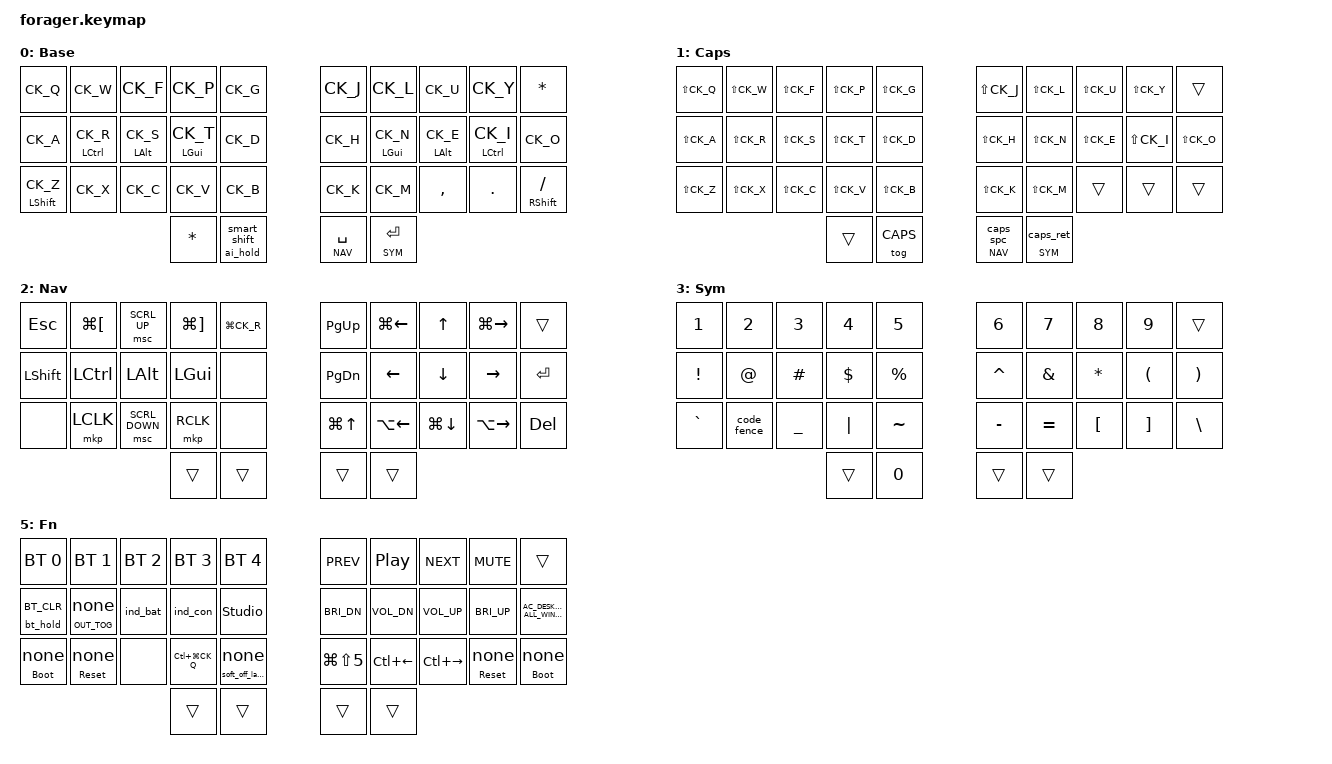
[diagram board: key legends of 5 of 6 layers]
/*
 * Forager keymap for a macOS, AI-agent and browser heavy workflow.
 *
 * Plain Colemak through the Mac's Colemak input source (see mac_colemak.h).
 * Layers: Base, Caps (caps word), Nav (hold Space), Sym (hold Enter),
 * AI (hold the shift thumb) and Fn (hold the shift thumb + Space).
 *
 * Two switches are dead on this board: the left outer thumb (30) and the
 * top-right key (9). Both type * on every layer, only so a repaired switch
 * is easy to test, and Backspace is the L + U combo.
 *
 * Key positions:
 *    0  1  2  3  4     5  6  7  8  9
 *   10 11 12 13 14    15 16 17 18 19
 *   20 21 22 23 24    25 26 27 28 29
 *            30 31    32 33
 */

#include <behaviors.dtsi>
#include <behaviors/rgbled_widget.dtsi>
#include <dt-bindings/zmk/keys.h>
#include <dt-bindings/zmk/bt.h>
#include <dt-bindings/zmk/outputs.h>
#include <dt-bindings/zmk/pointing.h>
#include "mac_colemak.h"

#define BASE 0
#define CAPS 1
#define NAV  2
#define SYM  3
#define AI   4
#define FN   5

#define KEYS_L 0 1 2 3 4 10 11 12 13 14 20 21 22 23 24
#define KEYS_R 5 6 7 8 9 15 16 17 18 19 25 26 27 28 29
#define THUMBS 30 31 32 33

&sk {
    release-after-ms = <600>;
    quick-release;
};

/ {
    behaviors {
        // Home-row mods (and the shift holds on Z and /) only fire with a key
        // from the other hand or a thumb, and never right after typing, so
        // fast rolls stay letters.
        hml: home_row_mod_left {
            compatible = "zmk,behavior-hold-tap";
            #binding-cells = <2>;
            flavor = "balanced";
            tapping-term-ms = <280>;
            quick-tap-ms = <175>;
            require-prior-idle-ms = <150>;
            hold-trigger-key-positions = <KEYS_R THUMBS>;
            hold-trigger-on-release;
            bindings = <&kp>, <&kp>;
        };
        hmr: home_row_mod_right {
            compatible = "zmk,behavior-hold-tap";
            #binding-cells = <2>;
            flavor = "balanced";
            tapping-term-ms = <280>;
            quick-tap-ms = <175>;
            require-prior-idle-ms = <150>;
            hold-trigger-key-positions = <KEYS_L THUMBS>;
            hold-trigger-on-release;
            bindings = <&kp>, <&kp>;
        };

        // Shift + Backspace deletes a word
        bspc_word: backspace_word {
            compatible = "zmk,behavior-mod-morph";
            #binding-cells = <0>;
            bindings = <&kp BSPC>, <&kp LA(BSPC)>;
            mods = <(MOD_LSFT|MOD_RSFT)>;
        };

        // Left inner thumb: tap for one-shot shift (twice for caps), hold
        // 1/4 s for AI. Tap-preferred, so only time picks AI: shift pressed
        // together with a letter always gives a capital, never a ⌘ shortcut.
        ai_shift: ai_shift {
            compatible = "zmk,behavior-hold-tap";
            #binding-cells = <2>;
            flavor = "tap-preferred";
            tapping-term-ms = <250>;
            quick-tap-ms = <175>;
            bindings = <&ai_hold>, <&smart_shift>;
        };

        // Space on the AI layer: hold for Fn. Hold-preferred with no idle
        // check, so it reaches Fn even when pressed right after the AI thumb.
        fn_spc: fn_space {
            compatible = "zmk,behavior-hold-tap";
            #binding-cells = <2>;
            flavor = "hold-preferred";
            tapping-term-ms = <200>;
            bindings = <&mo>, <&kp>;
        };

        // Right outer thumb: tap Enter, hold Sym. Hold-preferred, so a key
        // pressed during the hold always gives a symbol and never sends a
        // half-written prompt.
        sym_ret: sym_enter {
            compatible = "zmk,behavior-hold-tap";
            #binding-cells = <2>;
            flavor = "hold-preferred";
            tapping-term-ms = <170>;
            bindings = <&mo>, <&kp>;
        };
        sym_caps: sym_enter_caps {
            compatible = "zmk,behavior-hold-tap";
            #binding-cells = <2>;
            flavor = "hold-preferred";
            tapping-term-ms = <170>;
            bindings = <&mo>, <&caps_ret>;
        };

        // Right inner thumb: tap Space, hold Nav
        nav_spc: nav_space {
            compatible = "zmk,behavior-hold-tap";
            #binding-cells = <2>;
            flavor = "balanced";
            tapping-term-ms = <200>;
            quick-tap-ms = <175>;
            require-prior-idle-ms = <125>;
            bindings = <&mo>, <&kp>;
        };
        nav_caps: nav_space_caps {
            compatible = "zmk,behavior-hold-tap";
            #binding-cells = <2>;
            flavor = "balanced";
            tapping-term-ms = <200>;
            quick-tap-ms = <175>;
            require-prior-idle-ms = <125>;
            bindings = <&mo>, <&caps_spc>;
        };

        // One-shot shift, tap twice for caps word. Caps word is a layer
        // because ZMK's &caps_word won't shift CK_O (SEMI).
        smart_shift: smart_shift {
            compatible = "zmk,behavior-mod-morph";
            #binding-cells = <0>;
            bindings = <&sk LSHFT>, <&tog CAPS>;
            mods = <(MOD_LSFT|MOD_RSFT)>;
        };

        // ⌘ stays down from the first ⌘Tab until the AI thumb is released
        kt_on: key_toggle_on {
            compatible = "zmk,behavior-key-toggle";
            #binding-cells = <1>;
            toggle-mode = "on";
        };
        kt_off: key_toggle_off {
            compatible = "zmk,behavior-key-toggle";
            #binding-cells = <1>;
            toggle-mode = "off";
        };

        // Power, firmware and connection keys need a 1 s hold, so a slip
        // on Fn can't switch the output or drop a pairing
        off_hold: soft_off_hold {
            compatible = "zmk,behavior-hold-tap";
            #binding-cells = <2>;
            flavor = "tap-preferred";
            tapping-term-ms = <1000>;
            bindings = <&soft_off_later>, <&none>;
        };
        boot_hold: bootloader_hold {
            compatible = "zmk,behavior-hold-tap";
            #binding-cells = <2>;
            flavor = "tap-preferred";
            tapping-term-ms = <1000>;
            bindings = <&bootloader>, <&none>;
        };
        reset_hold: reset_hold {
            compatible = "zmk,behavior-hold-tap";
            #binding-cells = <2>;
            flavor = "tap-preferred";
            tapping-term-ms = <1000>;
            bindings = <&sys_reset>, <&none>;
        };
        bt_hold: bluetooth_hold {
            compatible = "zmk,behavior-hold-tap";
            #binding-cells = <2>;
            flavor = "tap-preferred";
            tapping-term-ms = <1000>;
            bindings = <&bt>, <&none>;
        };
        out_hold: output_hold {
            compatible = "zmk,behavior-hold-tap";
            #binding-cells = <2>;
            flavor = "tap-preferred";
            tapping-term-ms = <1000>;
            bindings = <&out>, <&none>;
        };
    };

    macros {
        // Off waits until the key is let go, then 2 s more. ⇧ and Space hold
        // Fn and are also the wake keys, and a wake key still down at
        // power-off switches that half straight back on.
        soft_off_later: soft_off_later {
            compatible = "zmk,behavior-macro";
            #binding-cells = <0>;
            wait-ms = <2000>;
            tap-ms = <10>;
            bindings
                = <&macro_pause_for_release>
                , <&macro_tap &none>
                , <&macro_tap &soft_off>
                ;
        };
        ai_hold: ai_hold {
            compatible = "zmk,behavior-macro";
            #binding-cells = <0>;
            wait-ms = <0>;
            tap-ms = <0>;
            bindings
                = <&macro_press &mo AI>
                , <&macro_pause_for_release>
                , <&macro_release &mo AI>
                , <&macro_tap &kt_off LGUI>
                ;
        };
        app_next: app_switch_next {
            compatible = "zmk,behavior-macro";
            #binding-cells = <0>;
            wait-ms = <10>;
            tap-ms = <20>;
            bindings = <&macro_tap &kt_on LGUI &kp TAB>;
        };
        esc_esc: escape_twice {
            compatible = "zmk,behavior-macro";
            #binding-cells = <0>;
            wait-ms = <30>;
            tap-ms = <30>;
            bindings = <&macro_tap &kp ESC &kp ESC>;
        };
        // Set System Settings › Keyboard › Dictation › Shortcut to
        // "Press Right Command Key Twice" (or the same in Wispr Flow / Superwhisper)
        dictate: dictate {
            compatible = "zmk,behavior-macro";
            #binding-cells = <0>;
            wait-ms = <40>;
            tap-ms = <30>;
            bindings = <&macro_tap &kp RGUI &kp RGUI>;
        };
        code_fence: code_fence {
            compatible = "zmk,behavior-macro";
            #binding-cells = <0>;
            wait-ms = <10>;
            tap-ms = <10>;
            bindings = <&macro_tap &kp GRAVE &kp GRAVE &kp GRAVE>;
        };
        caps_ret: caps_off_enter {
            compatible = "zmk,behavior-macro";
            #binding-cells = <0>;
            wait-ms = <0>;
            tap-ms = <10>;
            bindings = <&macro_tap &tog CAPS &kp RET>;
        };
        caps_spc: caps_off_space {
            compatible = "zmk,behavior-macro";
            #binding-cells = <0>;
            wait-ms = <0>;
            tap-ms = <10>;
            bindings = <&macro_tap &tog CAPS &kp SPACE>;
        };
    };

    combos {
        compatible = "zmk,combos";
        combo_esc {
            timeout-ms = <35>;
            require-prior-idle-ms = <150>;
            key-positions = <1 2>;
            bindings = <&kp ESC>;
            layers = <BASE CAPS>;
        };
        combo_tab {
            timeout-ms = <35>;
            require-prior-idle-ms = <150>;
            key-positions = <2 3>;
            bindings = <&kp TAB>;
            layers = <BASE CAPS>;
        };
        combo_cut {
            timeout-ms = <35>;
            require-prior-idle-ms = <150>;
            key-positions = <20 21>;
            bindings = <&kp LG(CK_X)>;
            layers = <BASE CAPS>;
        };
        combo_copy {
            timeout-ms = <35>;
            require-prior-idle-ms = <150>;
            key-positions = <21 22>;
            bindings = <&kp LG(CK_C)>;
            layers = <BASE CAPS>;
        };
        combo_paste {
            timeout-ms = <35>;
            require-prior-idle-ms = <150>;
            key-positions = <22 23>;
            bindings = <&kp LG(CK_V)>;
            layers = <BASE CAPS>;
        };
        combo_quote {
            timeout-ms = <35>;
            require-prior-idle-ms = <150>;
            key-positions = <7 8>;
            bindings = <&kp SQT>;
            layers = <BASE CAPS>;
        };
        // Backspace: hold both to repeat, shift first for a word. A shorter idle
        // than the other combos so quick repeated taps still register.
        combo_bspc {
            timeout-ms = <35>;
            require-prior-idle-ms = <120>;
            key-positions = <6 7>;
            bindings = <&bspc_word>;
            layers = <BASE CAPS>;
        };
        combo_semi {
            timeout-ms = <35>;
            require-prior-idle-ms = <150>;
            key-positions = <27 28>;
            bindings = <&kp CK_SEMI>;
            layers = <BASE CAPS>;
        };
        combo_colon {
            timeout-ms = <35>;
            require-prior-idle-ms = <150>;
            key-positions = <28 29>;
            bindings = <&kp CK_COLON>;
            layers = <BASE CAPS>;
        };
    };

    conditional_layers {
        compatible = "zmk,conditional-layers";
        fn_layer {
            if-layers = <AI NAV>;
            then-layer = <FN>;
        };
    };

    keymap {
        compatible = "zmk,keymap";

        base {
            display-name = "Base";
            bindings = <
            &kp CK_Q        &kp CK_W        &kp CK_F        &kp CK_P        &kp CK_G            &kp CK_J        &kp CK_L        &kp CK_U        &kp CK_Y        &kp STAR
            &kp CK_A        &hml LCTRL CK_R &hml LALT CK_S  &hml LGUI CK_T  &kp CK_D            &kp CK_H        &hmr LGUI CK_N  &hmr LALT CK_E  &hmr LCTRL CK_I &kp CK_O
            &hml LSHFT CK_Z &kp CK_X        &kp CK_C        &kp CK_V        &kp CK_B            &kp CK_K        &kp CK_M        &kp COMMA       &kp DOT         &hmr RSHFT FSLH
                                                            &kp STAR        &ai_shift 0 0       &nav_spc NAV SPACE &sym_ret SYM RET
            >;
        };

        caps {
            display-name = "Caps";
            bindings = <
            &kp LS(CK_Q)    &kp LS(CK_W)    &kp LS(CK_F)    &kp LS(CK_P)    &kp LS(CK_G)        &kp LS(CK_J)    &kp LS(CK_L)    &kp LS(CK_U)    &kp LS(CK_Y)    &trans
            &kp LS(CK_A)    &kp LS(CK_R)    &kp LS(CK_S)    &kp LS(CK_T)    &kp LS(CK_D)        &kp LS(CK_H)    &kp LS(CK_N)    &kp LS(CK_E)    &kp LS(CK_I)    &kp LS(CK_O)
            &kp LS(CK_Z)    &kp LS(CK_X)    &kp LS(CK_C)    &kp LS(CK_V)    &kp LS(CK_B)        &kp LS(CK_K)    &kp LS(CK_M)    &trans          &trans          &trans
                                                            &trans          &tog CAPS           &nav_caps NAV 0 &sym_caps SYM 0
            >;
        };

        nav {
            display-name = "Nav";
            bindings = <
            &kp ESC         &kp LG(LBKT)    &msc SCRL_UP    &kp LG(RBKT)    &kp LG(CK_R)        &kp PG_UP       &kp LG(LEFT)    &kp UP          &kp LG(RIGHT)   &trans
            &kp LSHFT       &kp LCTRL       &kp LALT        &kp LGUI        &none               &kp PG_DN       &kp LEFT        &kp DOWN        &kp RIGHT       &kp RET
            &none           &mkp LCLK       &msc SCRL_DOWN  &mkp RCLK       &none               &kp LG(UP)      &kp LA(LEFT)    &kp LG(DOWN)    &kp LA(RIGHT)   &kp DEL
                                                            &trans          &trans              &trans          &trans
            >;
        };

        sym {
            display-name = "Sym";
            bindings = <
            &kp N1          &kp N2          &kp N3          &kp N4          &kp N5              &kp N6          &kp N7          &kp N8          &kp N9          &trans
            &kp EXCL        &kp AT          &kp HASH        &kp DLLR        &kp PRCNT           &kp CARET       &kp AMPS        &kp STAR        &kp LPAR        &kp RPAR
            &kp GRAVE       &code_fence     &kp UNDER       &kp PIPE        &kp TILDE           &kp MINUS       &kp EQUAL       &kp LBKT        &kp RBKT        &kp BSLH
                                                            &trans          &kp N0              &trans          &trans
            >;
        };

        ai {
            display-name = "AI";
            bindings = <
            &kp LG(CK_W)    &kp LG(LS(LBKT)) &kp LG(LS(RBKT)) &kp LG(CK_T)  &kp LG(LS(CK_T))    &kp LG(LBKT)    &kp LG(RBKT)    &kp UP          &kp LG(LS(CK_Z)) &trans
            &kp LG(CK_A)    &kp ESC         &kp LS(TAB)     &app_next       &kp LG(GRAVE)       &kp LC(CK_C)    &kp LG(RET)     &kp DOWN        &kp LC(CK_V)    &kp LG(CK_K)
            &kp LG(CK_Z)    &kp LG(CK_X)    &kp LG(CK_C)    &kp LG(CK_V)    &kp LG(LC(LS(N4)))  &esc_esc        &kp LC(CK_R)    &kp LS(RET)     &kp LG(SPACE)   &dictate
                                                            &trans          &trans              &fn_spc NAV SPACE &kp LG(BSPC)
            >;
        };

        fn {
            display-name = "Fn";
            bindings = <
            &bt BT_SEL 0    &bt BT_SEL 1    &bt BT_SEL 2    &bt BT_SEL 3    &bt BT_SEL 4        &kp C_PREV      &kp C_PP        &kp C_NEXT      &kp C_MUTE      &trans
            &bt_hold BT_CLR &out_hold OUT_TOG 0 &ind_bat        &ind_con        &studio_unlock      &kp C_BRI_DN    &kp C_VOL_DN    &kp C_VOL_UP    &kp C_BRI_UP    &kp C_AC_DESKTOP_SHOW_ALL_WINDOWS
            &boot_hold 0 0  &reset_hold 0 0 &none           &kp LC(LG(CK_Q)) &off_hold 0 0       &kp LG(LS(N5))  &kp LC(LEFT)    &kp LC(RIGHT)   &reset_hold 0 0 &boot_hold 0 0
                                                            &trans          &trans              &trans          &trans
            >;
        };
    };
};
